# GD32H71x_72x register map
File version: 1.0
CPU: CM7 r1p2, little endian, MPU, FPU, 4 interrupt priority bits
Registers are 32-bit, read-write, reset 0x0 unless marked. A register's access mark holds for its fields unless they carry their own. Offsets are from the block's base; [hi:lo] are bit positions; {n}, {i} and the like mark numbered series.

## SDIO0 — Secure digital input/output interface
Base 0x52007000
Same registers: SDIO1 0x48022400
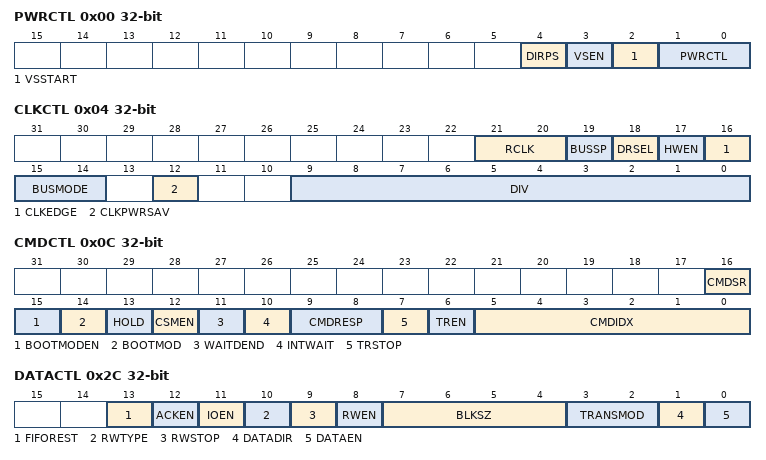
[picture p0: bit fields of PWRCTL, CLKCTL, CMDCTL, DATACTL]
0x00 PWRCTL — Power control register
  [4] DIRPS — Command and data direction polarity selection bit
  [3] VSEN — Voltage switch enable bit
  [2] VSSTART — Voltage switch start bit
  [1:0] PWRCTL — SDIO power control bits
0x04 CLKCTL — Clock control register
  [21:20] RCLK — Receive clock selection bits
  [19] BUSSP — Bus speed mode selection bit
  [18] DRSEL — Data rate selection bit
  [17] HWEN — Hardware flow control enable bit
  [16] CLKEDGE — Command and data SDIO_CLK dephasing selection bit
  [15:14] BUSMODE — SDIO card bus mode control bit
  [12] CLKPWRSAV — SDIO_CLK clock dynamic switch on/off for power saving.
  [9:0] DIV — Clock division
0x08 CMDAGMT — Command argument register
  [31:0] CMDAGMT — SDIO card command argument
0x0C CMDCTL — Command control register
  [16] CMDSR — Suspend or Resume command and signals interrupt period start/end bit.
  [15] BOOTMODEN — Boot mode procedure enable bit
  [14] BOOTMOD — Boot mode selection bit
  [13] HOLD — Hold DSM transmission and reception of new data block
  [12] CSMEN — Command state machine (CSM) enable bit
  [11] WAITDEND — Waits for ends of data transfer
  [10] INTWAIT — Interrupt wait request
  [9:8] CMDRESP — Waits command response type bits
  [7] TRSTOP — Data transfer stop command mode enable bit
  [6] TREN — Data transfer command mode enable bit
  [5:0] CMDIDX — Command index
0x10 RSPCMDIDX ro — Command index response register
  [5:0] RSPCMDIDX — Last response command index
{0x14+4i} RESP{i} ro (i=0..3) — Response regist {i}
  [31:0] RESP — The content of the last card response received
0x24 DATATO — Data timeout register
  [31:0] DATATO — Data timeout period
0x28 DATALEN — Data length register
  [24:0] DATALEN — Data transfer length
0x2C DATACTL — Data control register
  [13] FIFOREST — FIFO buffer reset, flush all data
  [12] ACKEN — Boot acknowledgment enable bit
  [11] IOEN — SD I/O specific function enable(SD I/O only)
  [10] RWTYPE — Read wait type(SD I/O only)
  [9] RWSTOP — Read wait stop(SD I/O only)
  [8] RWEN — Read wait mode enabled(SD I/O only)
  [7:4] BLKSZ — Data block size
  [3:2] TRANSMOD — Data transfer mode
  [1] DATADIR — Data transfer direction
  [0] DATAEN — Data transfer enable bit
0x30 DATACNT ro — Data counter register
  [24:0] DATACNT — Data count value
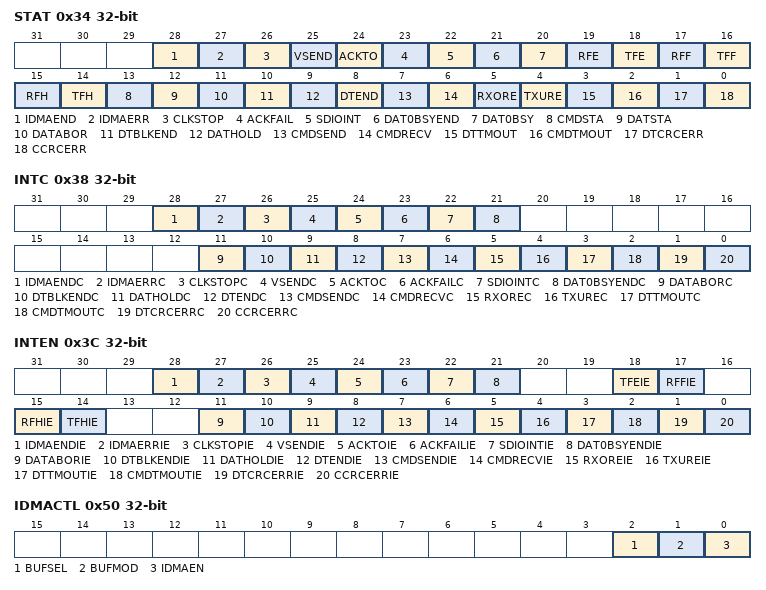
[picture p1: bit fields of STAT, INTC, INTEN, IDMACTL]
0x34 STAT ro — Status register
  [28] IDMAEND — IDMA transfer end
  [27] IDMAERR — IDMA transfer error
  [26] CLKSTOP — SDIO_CLK stopped in Voltage Switch procedure
  [25] VSEND — Voltage Switch critical timing section end
  [24] ACKTO — Boot acknowledgment timeout
  [23] ACKFAIL — Boot acknowledgment received and check fail
  [22] SDIOINT — SD I/O interrupt received
  [21] DAT0BSYEND — End of CMD response, card DAT0 line signal changed from busy to ready.
  [20] DAT0BSY — End of CMD response and a second time 2 clock cycles after the CMD response, card signals busy on DAT0 line.
  [19] RFE — Receive FIFO is empty
  [18] TFE — Transmit FIFO is empty
  [17] RFF — Receive FIFO is full
  [16] TFF — Transmit FIFO is full
  [15] RFH — Receive FIFO is half full: at least half the number of words can be read in the FIFO
  [14] TFH — Transmit FIFO is half empty: at least half the number of words can be written into the FIFO.
  [13] CMDSTA — Command path active state
  [12] DATSTA — Data path active state
  [11] DATABOR — Data transfer aborted by CMD12
  [10] DTBLKEND — Data block sent/received (CRC check passed)
  [9] DATHOLD — Data transfer hold
  [8] DTEND — Data end (data counter, SDIO_DATACNT is zero)
  [7] CMDSEND — Command sent (no response required)
  [6] CMDRECV — Command response received (CRC check passed)
  [5] RXORE — Received FIFO overrun error occurs
  [4] TXURE — Transmit FIFO underrun error occurs
  [3] DTTMOUT — Data timeout
  [2] CMDTMOUT — Command response timeout
  [1] DTCRCERR — Data block sent/received (CRC check failed)
  [0] CCRCERR — Command response received (CRC check failed)
0x38 INTC wo — Interrupt clear register
  [28] IDMAENDC — IDMAEND flag clear bit
  [27] IDMAERRC — IDMAERR flag clear bit
  [26] CLKSTOPC — CLKSTOP flag clear bit
  [25] VSENDC — VSEND flag clear bit
  [24] ACKTOC — ACKTO flag clear bit
  [23] ACKFAILC — ACKFAIL flag clear bit
  [22] SDIOINTC — SDIOINT flag clear bit
  [21] DAT0BSYENDC — DAT0BSYEND flag clear bit
  [11] DATABORC — DATABOR flag clear bit
  [10] DTBLKENDC — DTBLKEND flag clear bit
  [9] DATHOLDC — DATHOLD flag clear bit
  [8] DTENDC — DTEND flag clear bit
  [7] CMDSENDC — CMDSEND flag clear bit
  [6] CMDRECVC — CMDRECV flag clear bit
  [5] RXOREC — RXORE flag clear bit
  [4] TXUREC — TXURE flag clear bit
  [3] DTTMOUTC — DTTMOUT flag clear bit
  [2] CMDTMOUTC — CMDTMOUT flag clear bit
  [1] DTCRCERRC — DTCRCERR flag clear bit
  [0] CCRCERRC — CCRCERR flag clear bit
0x3C INTEN — Interrupt enable register
  [28] IDMAENDIE — IDMA transfer end interrupt enable
  [27] IDMAERRIE — IDMA transfer error interrupt enable
  [26] CLKSTOPIE — Voltage Switch clock stopped interrupt enable
  [25] VSENDIE — Voltage Switch critical timing section end interrupt enable
  [24] ACKTOIE — Boot acknowledgment timeout enable
  [23] ACKFAILIE — Boot acknowledgment received and check fail interrupt enable
  [22] SDIOINTIE — SD I/O interrupt received interrupt enable
  [21] DAT0BSYENDIE — DAT0 line signal changed from busy to ready interrupt enable.
  [18] TFEIE — Transmit FIFO empty interrupt enable
  [17] RFFIE — Receive FIFO full interrupt enable
  [15] RFHIE — Receive FIFO half full interrupt enable
  [14] TFHIE — Transmit FIFO half empty interrupt enable
  [11] DATABORIE — Data transfer abort interrupt enable
  [10] DTBLKENDIE — Data block end interrupt enable
  [9] DATHOLDIE — Data hold interrupt enable
  [8] DTENDIE — Data end interrupt enable
  [7] CMDSENDIE — Command sent interrupt enable
  [6] CMDRECVIE — Command response received interrupt enable
  [5] RXOREIE — Received FIFO overrun error interrupt enable
  [4] TXUREIE — Transmit FIFO underrun error interrupt enable
  [3] DTTMOUTIE — Data timeout interrupt enable
  [2] CMDTMOUTIE — Command response timeout interrupt enable
  [1] DTCRCERRIE — Data CRC fail interrupt enable
  [0] CCRCERRIE — Command response CRC fail interrupt enable
0x40 ACKTO — ACK timeout register
  [24:0] ACKTO — Boot ACK timeout period.
0x50 IDMACTL — IDMA control register
  [2] BUFSEL — IDMA double buffer selection bit
  [1] BUFMOD — Double buffer selection bit
  [0] IDMAEN — FIFO internal DMA enable bit
0x54 IDMASIZE — IDMA buffer size register
  [12:5] IDMASIZE — Number of bytes per buffer.
0x58 IDMAADDR0 — IDMA buffer 0 base address register
  [31:0] IDMAADDR0 — The address is a multiple of 4. The IDMAADDR0[1:0] are always 0 and read only.
0x5C IDMAADDR1 — IDMA buffer 1 base address register
  [31:0] IDMAADDR1 — The address is a multiple of 4. The IDMAADDR1[1:0] are always 0 and read only.
0x80 FIFO — FIFO data register
  [31:0] FIFODT — Receive FIFO data or transmit FIFO data
